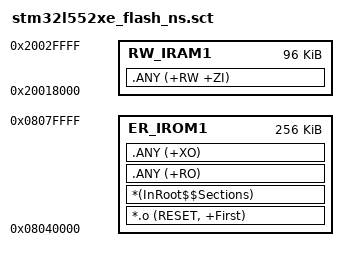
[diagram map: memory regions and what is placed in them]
; *************************************************************
; *** Scatter-Loading Description File generated by uVision ***
; *************************************************************

LR_IROM1 0x08040000 0x00040000  {    ; load region size_region
  ER_IROM1 0x08040000 0x00040000  {  ; load address = execution address
   *.o (RESET, +First)
   *(InRoot$$Sections)
   .ANY (+RO)
   .ANY (+XO)
  }
  RW_IRAM1 0x20018000 0x00018000  {  ; RW data
   .ANY (+RW +ZI)
  }
}

